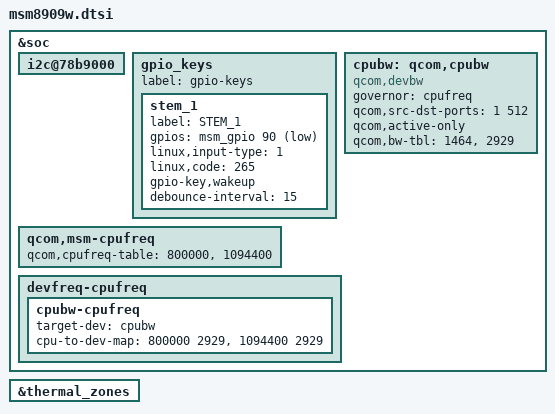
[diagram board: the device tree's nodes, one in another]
/* Copyright (c) 2015-2018, The Linux Foundation. All rights reserved.
 *
 * This program is free software; you can redistribute it and/or modify
 * it under the terms of the GNU General Public License version 2 and
 * only version 2 as published by the Free Software Foundation.
 *
 * This program is distributed in the hope that it will be useful,
 * but WITHOUT ANY WARRANTY; without even the implied warranty of
 * MERCHANTABILITY or FITNESS FOR A PARTICULAR PURPOSE.  See the
 * GNU General Public License for more details.
 */

&soc {
	i2c@78b9000 { /* BLSP1 QUP5 */
		/delete-node/ synaptics@20;
	};

	gpio_keys {
		label = "gpio-keys";
		/delete-node/ camera_focus;
		/delete-node/ camera_snapshot;
		/delete-node/ vol_up;
		stem_1 {
			label = "STEM_1";
			gpios = <&msm_gpio 90 0x1>;
			linux,input-type = <1>;
			linux,code = <265>;
			gpio-key,wakeup;
			debounce-interval = <15>;
		};
	};
};
&soc {
	qcom,msm-cpufreq {
		/delete-property/ qcom,cpufreq-table;
		qcom,cpufreq-table =
			<  800000 >,
			< 1094400 >;
	};
	/delete-node/ qcom,cpubw;
	cpubw: qcom,cpubw {
		compatible = "qcom,devbw";
		governor = "cpufreq";
		qcom,src-dst-ports = <1 512>;
		qcom,active-only;
		qcom,bw-tbl =
			< 1464 /* 192 MHz */>,
			< 2929 /* 384 MHz */>;
	};
	/delete-node/ devfreq-cpufreq;
	devfreq-cpufreq {
		cpubw-cpufreq {
			target-dev = <&cpubw>;
			cpu-to-dev-map =
				<  800000  2929>,
				< 1094400  2929>;
		};
	};
};

&thermal_zones {
	/delete-node/ case-therm-step;
};


